# S32K322_M7 register map
Vendor: NXP Semiconductors; File version: 1.0
CPU: CM7 r0p1, little endian, MPU, FPU, VTOR, 4 interrupt priority bits
Registers are 32-bit, read-write, reset 0x0 unless marked. A register's access mark holds for its fields unless they carry their own. Offsets are from the block's base; [hi:lo] are bit positions; {n}, {i} and the like mark numbered series; 'fields as' and 'values as' point back to an identical list.

## DCM
Base 0x402AC000
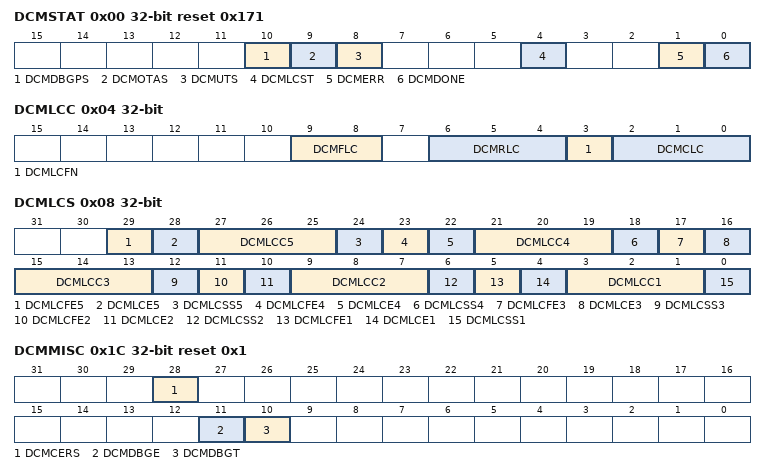
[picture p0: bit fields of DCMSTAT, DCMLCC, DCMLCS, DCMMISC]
0x00 DCMSTAT ro reset 0x171 (reset mask 0xFFFFFDFF) — DCM Status
  [10] DCMDBGPS — Debug Password Scanning Status
    0=Completed with errors; 1=Completed successfully
  [9] DCMOTAS — DCM OTA Scanning Status (valid only when the value of the DCMDONE field is 1)
    0=Completed with errors; 1=Completed successfully
  [8] DCMUTS — DCM Utest DCF Scanning Status (valid only if DCMDONE bit is set)
    0=DCM Utest DCF completed with errors; 1=DCM Utest DCF completed successfully
  [4] DCMLCST — LC Scanning Status
    0=Completed with errors; 1=Completed successfully
  [1] DCMERR — DCM completion with error status (valid only if DCMDONE bit is set)
    0=DCM completed with success; 1=DCM completed with error
  [0] DCMDONE — DCM Scanning Status
    0=Running; 1=Completed
0x04 DCMLCC (reset mask 0xFFFFFF88) — LC and LC Control
  [9:8] DCMFLC — Force Next LC
    0=No force; 1=Force LC to one next; 2=Force LC to two next (only possible in CD)
  [6:4] DCMRLC ro — Real LC
    0=FA; 1=Pre-FA; 2=OEM_PROD; 3=CUST_DEL; 6=MCU_PROD; 7=IN_FIELD
  [3] DCMLCFN — Force LC
    0=Normal; 1=Forced on current LC
  [2:0] DCMCLC ro — Current LC
    values as DCMRLC
0x08 DCMLCS write-1-clears — LC Scan Status
  [29] DCMLCFE5 write-1-clears — Pre-FA Flash Memory Error Check
    0=Successful; 1=Failed
  [28] DCMLCE5 write-1-clears — Pre-FA ECC Errors
    0=No errors; 1=Marking error
  [27:25] DCMLCC5 write-1-clears — Pre-FA Marking Status
    0=Not scanned yet; 1=Marked as active; 2=Marked as inactive; 3=Region is erased/virgin; 5=Marked as inactive by an unknown pattern; 6=Scanning timed out
  [24] DCMLCSS5 write-1-clears — Pre-FA Scan Status
    0=Successful; 1=Errors exist
  [23] DCMLCFE4 write-1-clears — IN_FIELD Flash Memory Error Check
    0=Successful; 1=Failed
  [22] DCMLCE4 write-1-clears — IN_FIELD ECC Errors
    0=No errors; 1=Errors exist
  [21:19] DCMLCC4 write-1-clears — IN_FIELD Marking Status
    values as DCMLCC5
  [18] DCMLCSS4 write-1-clears — IN_FIELD Scan Status
    0=No errors; 1=Errors exist
  [17] DCMLCFE3 write-1-clears — OEM_PROD Flash Memory Error Check
    0=Successful; 1=Failed
  [16] DCMLCE3 write-1-clears — OEM_PROD ECC Errors
    0=No errors; 1=Errors exist
  [15:13] DCMLCC3 write-1-clears — OEM_PROD Marking
    values as DCMLCC5
  [12] DCMLCSS3 write-1-clears — OEM_PROD Scan Status
    0=No errors; 1=Errors exist
  [11] DCMLCFE2 write-1-clears — CUST_DEL Flash Memory Error Check
    0=Successful; 1=Failed
  [10] DCMLCE2 write-1-clears — ECC Errors In CUST_DEL
    0=No errors; 1=Errors exist
  [9:7] DCMLCC2 write-1-clears — CUST_DEL Marking
    values as DCMLCC5
  [6] DCMLCSS2 write-1-clears — CUST_DEL Scan Status
    0=No errors; 1=Errors exist
  [5] DCMLCFE1 write-1-clears — MCU_PROD Flash Memory Error Check
    0=Successful; 1=Failed
  [4] DCMLCE1 write-1-clears — MCU_PROD ECC Errors
    0=No errors; 1=Errors exist
  [3:1] DCMLCC1 write-1-clears — MCU_PROD Marking
    values as DCMLCC5
  [0] DCMLCSS1 write-1-clears — MCU_PROD Scan Status
    0=No errors; 1=Errors exist
0x1C DCMMISC reset 0x1 write-1-clears — DCM Miscellaneous
  [28] DCMCERS write-1-clears — DCF Client Errors
    0=No errors on any of the DCF clients; 1=Atleast one safety DCF client has an error
  [11] DCMDBGE write-1-clears — DCM ECC error on DBG sections
    0=No error on DBG section; 1=DBG section error
  [10] DCMDBGT write-1-clears — DBG Section Error
    0=No error; 1=Error exists
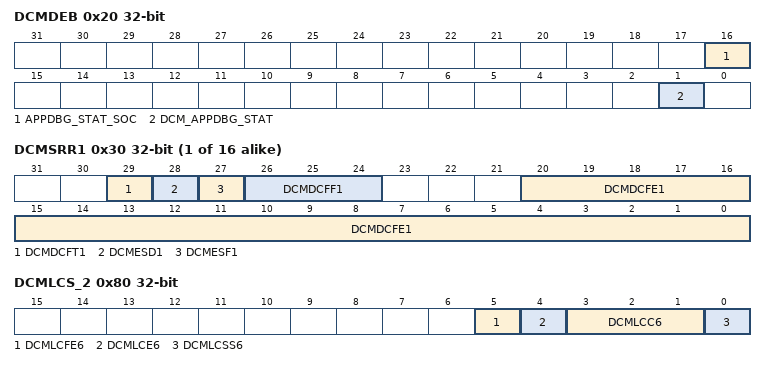
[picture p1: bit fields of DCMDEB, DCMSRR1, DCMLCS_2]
0x20 DCMDEB — Debug Status and Configuration
  [16] APPDBG_STAT_SOC ro — Application Debug Status
    0=Disabled; 1=Enabled
  [1] DCM_APPDBG_STAT ro — DCM Authentication Engine Status
    0=Disabled; 1=Enabled
0x2C DCMEC ro — DCF Error Count
  [15:0] DCMECT — Error Count
{0x2C+4i} DCMSRR{i} (i=1..16) write-1-clears — DCF Scan Report
  [29] DCMDCFT1 write-1-clears — Scanning Timeout On Flash Memory
    0=Does not exist; 1=Exists
  [28] DCMESD1 write-1-clears — Chip Side Error
    0=No errors; 1=Errors exist
  [27] DCMESF1 write-1-clears — Flash Memory Error
    0=No errors; 1=Errors exist
  [26:24] DCMDCFF1 write-1-clears — DCF Record Location
    2=Utest region; 5=Others: Reserved
  [20:0] DCMDCFE1 write-1-clears — Flash Memory Address
0x80 DCMLCS_2 write-1-clears — LC Scan Status 2
  [5] DCMLCFE6 write-1-clears — Flash Memory Error Check
    0=Successful; 1=Failed
  [4] DCMLCE6 write-1-clears — FA ECC Errors
    0=No errors; 1=Errors exist
  [3:1] DCMLCC6 write-1-clears — FA Marking
    values as DCMLCS.DCMLCC5
  [0] DCMLCSS6 write-1-clears — FA Scan Status
    0=No errors; 1=Errors exist
